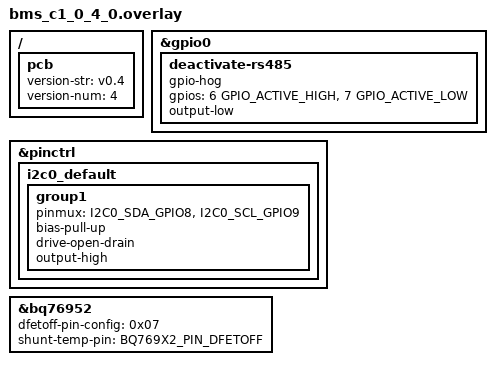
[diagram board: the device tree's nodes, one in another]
/*
 * Copyright (c) The Libre Solar Project Contributors
 *
 * SPDX-License-Identifier: Apache-2.0
 */

#include <dt-bindings/bms_ic/bq769x2.h>

/ {
	pcb {
		version-str = "v0.4";
		version-num = <4>;
	};
};

&gpio0 {
	deactivate-rs485 {
		gpio-hog;
		gpios = <6 GPIO_ACTIVE_HIGH>, <7 GPIO_ACTIVE_LOW>;
		output-low;
	};
};

&pinctrl {
	i2c0_default: i2c0_default {
		group1 {
			pinmux = <I2C0_SDA_GPIO8>,
				 <I2C0_SCL_GPIO9>;
			bias-pull-up;
			drive-open-drain;
			output-high;
		};
	};
};

&bq76952 {
	/* DFETOFF wired to shunt NTC on v0.4 only */
	dfetoff-pin-config = <0x07>;
	shunt-temp-pin = <BQ769X2_PIN_DFETOFF>;
};
